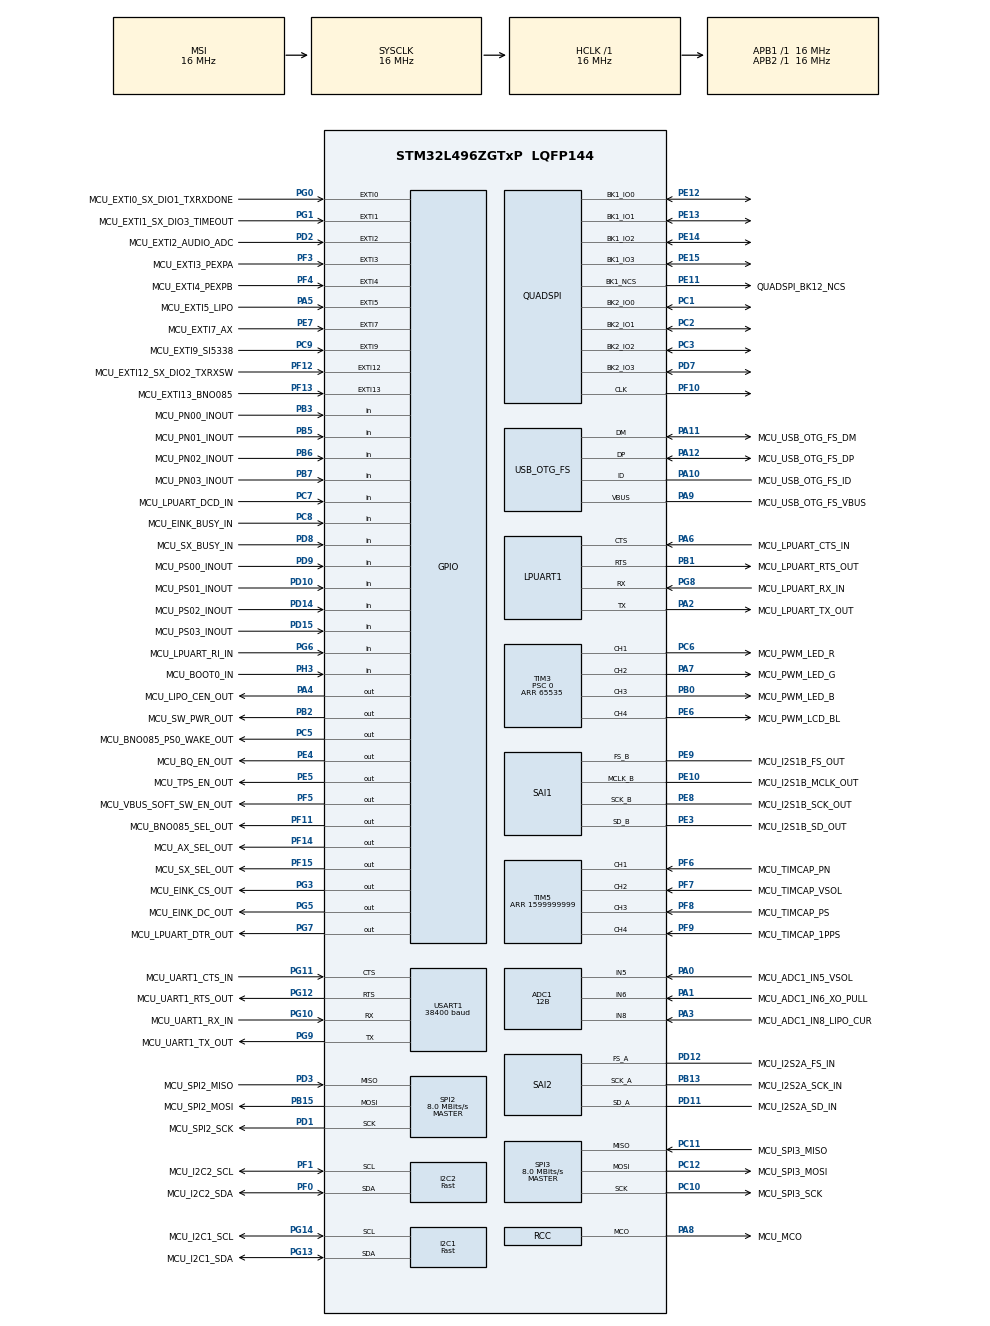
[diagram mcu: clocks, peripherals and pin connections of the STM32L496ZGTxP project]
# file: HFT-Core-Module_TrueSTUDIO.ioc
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ADC1.Channel-355\#ChannelRegularConversion=ADC_CHANNEL_VREFINT
ADC1.Channel-356\#ChannelRegularConversion=ADC_CHANNEL_8
ADC1.Channel-357\#ChannelRegularConversion=ADC_CHANNEL_VBAT
ADC1.Channel-358\#ChannelRegularConversion=ADC_CHANNEL_TEMPSENSOR
ADC1.ClockPrescaler=ADC_CLOCK_ASYNC_DIV1
ADC1.ContinuousConvMode=DISABLE
ADC1.DMAContinuousRequests=ENABLE
ADC1.DataAlign=ADC_DATAALIGN_RIGHT
ADC1.DiscontinuousConvMode=DISABLE
ADC1.EOCSelection=ADC_EOC_SINGLE_CONV
ADC1.EnableAnalogWatchDog1=false
ADC1.EnableAnalogWatchDog2=false
ADC1.EnableAnalogWatchDog3=false
ADC1.EnableInjectedConversion=DISABLE
ADC1.EnableRegularConversion=ENABLE
ADC1.ExternalTrigConv=ADC_SOFTWARE_START
ADC1.ExternalTrigConvEdge=ADC_EXTERNALTRIGCONVEDGE_NONE
ADC1.LowPowerAutoWait=DISABLE
ADC1.NbrOfConversion=4
ADC1.NbrOfConversionFlag=1
ADC1.OffsetNumber-355\#ChannelRegularConversion=ADC_OFFSET_NONE
ADC1.OffsetNumber-356\#ChannelRegularConversion=ADC_OFFSET_NONE
ADC1.OffsetNumber-357\#ChannelRegularConversion=ADC_OFFSET_NONE
ADC1.OffsetNumber-358\#ChannelRegularConversion=ADC_OFFSET_NONE
ADC1.Overrun=ADC_OVR_DATA_PRESERVED
ADC1.OversamplingMode=ENABLE
ADC1.OversamplingStopReset=ADC_REGOVERSAMPLING_CONTINUED_MODE
ADC1.Rank-355\#ChannelRegularConversion=1
ADC1.Rank-356\#ChannelRegularConversion=2
ADC1.Rank-357\#ChannelRegularConversion=3
ADC1.Rank-358\#ChannelRegularConversion=4
ADC1.Ratio=ADC_OVERSAMPLING_RATIO_16
ADC1.Resolution=ADC_RESOLUTION_12B
ADC1.RightBitShift=ADC_RIGHTBITSHIFT_NONE
ADC1.SamplingTime-355\#ChannelRegularConversion=ADC_SAMPLETIME_12CYCLES_5
ADC1.SamplingTime-356\#ChannelRegularConversion=ADC_SAMPLETIME_12CYCLES_5
ADC1.SamplingTime-357\#ChannelRegularConversion=ADC_SAMPLETIME_247CYCLES_5
ADC1.SamplingTime-358\#ChannelRegularConversion=ADC_SAMPLETIME_12CYCLES_5
ADC1.ScanConvMode=ADC_SCAN_ENABLE
ADC1.TriggeredMode=ADC_TRIGGEREDMODE_SINGLE_TRIGGER
ADC1.master=1
DFSDM1.Filter_regChannel_FIL0=DFSDM_CHANNEL_0
DFSDM1.Filter_regChannel_FIL1=DFSDM_CHANNEL_1
DFSDM1.Filter_regContinuousMode_FIL0=DFSDM_CONTINUOUS_CONV_OFF
DFSDM1.Filter_regContinuousMode_FIL1=DFSDM_CONTINUOUS_CONV_OFF
Dma.ADC1.2.Direction=DMA_PERIPH_TO_MEMORY
Dma.ADC1.2.Instance=DMA1_Channel1
Dma.ADC1.2.MemDataAlignment=DMA_MDATAALIGN_HALFWORD
Dma.ADC1.2.MemInc=DMA_MINC_ENABLE
Dma.ADC1.2.Mode=DMA_NORMAL
Dma.ADC1.2.PeriphDataAlignment=DMA_PDATAALIGN_HALFWORD
Dma.ADC1.2.PeriphInc=DMA_PINC_DISABLE
Dma.ADC1.2.Priority=DMA_PRIORITY_LOW
Dma.Request0=SAI2_A
Dma.Request1=SAI1_B
Dma.Request2=ADC1
Dma.Request3=SPI3_RX
Dma.Request4=SPI3_TX
Dma.SAI1_B.1.Direction=DMA_MEMORY_TO_PERIPH
Dma.SAI1_B.1.Instance=DMA2_Channel7
Dma.SAI1_B.1.MemDataAlignment=DMA_MDATAALIGN_WORD
Dma.SAI1_B.1.MemInc=DMA_MINC_ENABLE
Dma.SAI1_B.1.Mode=DMA_NORMAL
Dma.SAI1_B.1.PeriphDataAlignment=DMA_PDATAALIGN_WORD
Dma.SAI1_B.1.PeriphInc=DMA_PINC_DISABLE
Dma.SAI1_B.1.Priority=DMA_PRIORITY_LOW
Dma.SAI2_A.0.Direction=DMA_PERIPH_TO_MEMORY
Dma.SAI2_A.0.Instance=DMA1_Channel6
Dma.SAI2_A.0.MemDataAlignment=DMA_MDATAALIGN_WORD
Dma.SAI2_A.0.MemInc=DMA_MINC_ENABLE
Dma.SAI2_A.0.Mode=DMA_NORMAL
Dma.SAI2_A.0.PeriphDataAlignment=DMA_PDATAALIGN_WORD
Dma.SAI2_A.0.PeriphInc=DMA_PINC_DISABLE
Dma.SAI2_A.0.Priority=DMA_PRIORITY_LOW
Dma.SPI3_RX.3.Direction=DMA_PERIPH_TO_MEMORY
Dma.SPI3_RX.3.Instance=DMA2_Channel1
Dma.SPI3_RX.3.MemDataAlignment=DMA_MDATAALIGN_BYTE
Dma.SPI3_RX.3.MemInc=DMA_MINC_ENABLE
Dma.SPI3_RX.3.Mode=DMA_NORMAL
Dma.SPI3_RX.3.PeriphDataAlignment=DMA_PDATAALIGN_BYTE
Dma.SPI3_RX.3.PeriphInc=DMA_PINC_DISABLE
Dma.SPI3_RX.3.Priority=DMA_PRIORITY_LOW
Dma.SPI3_TX.4.Direction=DMA_MEMORY_TO_PERIPH
Dma.SPI3_TX.4.Instance=DMA2_Channel2
Dma.SPI3_TX.4.MemDataAlignment=DMA_MDATAALIGN_BYTE
Dma.SPI3_TX.4.MemInc=DMA_MINC_ENABLE
Dma.SPI3_TX.4.Mode=DMA_NORMAL
Dma.SPI3_TX.4.PeriphDataAlignment=DMA_PDATAALIGN_BYTE
Dma.SPI3_TX.4.PeriphInc=DMA_PINC_DISABLE
Dma.SPI3_TX.4.Priority=DMA_PRIORITY_LOW
FREERTOS.BinarySemaphores01=c2Ax5243_BSem,Dynamic,NULL;c2Sx1276_BSem,Dynamic,NULL;c2Si5338_BSem,Dynamic,NULL;c2Tcxo_BSem,Dynamic,NULL;c2Baro_BSem,Dynamic,NULL;c2Gyro_BSem,Dynamic,NULL;c2Hygro_BSem,Dynamic,NULL;c2Lcd_BSem,Dynamic,NULL;c2Default_BSem,Dynamic,NULL;i2c1_BSem,Dynamic,NULL;i2c2_BSem,Dynamic,NULL;i2c3_BSem,Dynamic,NULL;i2c4_BSem,Dynamic,NULL;spi1_BSem,Dynamic,NULL;spi3_BSem,Dynamic,NULL;cQin_BSem,Dynamic,NULL;cQout_BSem,Dynamic,NULL;c2AudioAdc_BSem,Dynamic,NULL;c2AudioDac_BSem,Dynamic,NULL;c2usbToHost_BSem,Dynamic,NULL;c2usbFromHost_BSem,Dynamic,NULL;usb_BSem,Dynamic,NULL
FREERTOS.INCLUDE_eTaskGetState=1
FREERTOS.INCLUDE_pcTaskGetTaskName=1
FREERTOS.INCLUDE_uxTaskGetStackHighWaterMark=1
FREERTOS.INCLUDE_vTaskCleanUpResources=1
FREERTOS.INCLUDE_vTaskDelayUntil=1
FREERTOS.INCLUDE_vTaskDelete=1
FREERTOS.INCLUDE_xEventGroupSetBitFromISR=1
FREERTOS.INCLUDE_xQueueGetMutexHolder=1
FREERTOS.INCLUDE_xSemaphoreGetMutexHolder=1
FREERTOS.INCLUDE_xTaskAbortDelay=1
FREERTOS.INCLUDE_xTaskGetCurrentTaskHandle=1
FREERTOS.INCLUDE_xTaskGetHandle=1
FREERTOS.INCLUDE_xTimerPendFunctionCall=1
FREERTOS.Queues01=usbToHostQueue,4096,uint8_t,0,Dynamic,NULL,NULL;usbFromHostQueue,32,uint8_t,0,Dynamic,NULL,NULL;controllerInQueue,8,uint32_t,0,Dynamic,NULL,NULL;controllerOutQueue,32,uint32_t,0,Dynamic,NULL,NULL;loraMacQueue,32,uint8_t,0,Dynamic,NULL,NULL
FREERTOS.Tasks01=defaultTask,-1,256,StartDefaultTask,Default,NULL,Dynamic,NULL,NULL;usbToHostTask,0,128,StartUsbToHostTask,Default,NULL,Dynamic,NULL,NULL;usbFromHostTask,0,128,StartUsbFromHostTask,Default,NULL,Dynamic,NULL,NULL;hygroTask,0,256,StartHygroTask,Default,NULL,Dynamic,NULL,NULL;baroTask,0,256,StartBaroTask,Default,NULL,Dynamic,NULL,NULL;gyroTask,0,256,StartGyroTask,Default,NULL,Dynamic,NULL,NULL;lcdTask,0,256,StartLcdTask,Default,NULL,Dynamic,NULL,NULL;tcxo20MhzTask,0,256,StartTcxo20MhzTask,Default,NULL,Dynamic,NULL,NULL;ax5243Task,1,512,StartAx5243Task,Default,NULL,Dynamic,NULL,NULL;sx1276Task,1,512,StartSx1276Task,Default,NULL,Dynamic,NULL,NULL;controllerTask,-2,256,StartControllerTask,Default,NULL,Dynamic,NULL,NULL;si5338Task,0,256,StartSi5338Task,Default,NULL,Dynamic,NULL,NULL;audioAdcTask,0,256,StartAudioAdcTask,Default,NULL,Dynamic,NULL,NULL;audioDacTask,0,256,StartAudioDacTask,Default,NULL,Dynamic,NULL,NULL
FREERTOS.Timers01=baroTimer,rtosBaroTimerCallback,osTimerPeriodic,Default,NULL,Dynamic,NULL;hygroTimer,rtosHygroTimerCallback,osTimerPeriodic,Default,NULL,Dynamic,NULL;defaultTimer,rtosDefaultTimerCallback,osTimerPeriodic,Default,NULL,Dynamic,NULL;gyroTimer,rtosGyroTimerCallback,osTimerPeriodic,Default,NULL,Dynamic,NULL;controllerTimer,rtosControllerTimerCallback,osTimerPeriodic,Default,NULL,Dynamic,NULL;tcxoTimer,rtosTcxoTimerCallback,osTimerPeriodic,Default,NULL,Dynamic,NULL;audioAdcTimer,rtosAudioAdcTimerCallback,osTimerPeriodic,Default,NULL,Dynamic,NULL;audioDacTimer,rtosAudioDacTimerCallback,osTimerPeriodic,Default,NULL,Dynamic,NULL
FREERTOS.configCHECK_FOR_STACK_OVERFLOW=1
FREERTOS.configENABLE_BACKWARD_COMPATIBILITY=0
FREERTOS.configGENERATE_RUN_TIME_STATS=1
FREERTOS.configMAX_TASK_NAME_LEN=32
FREERTOS.configQUEUE_REGISTRY_SIZE=64
FREERTOS.configTIMER_QUEUE_LENGTH=16
FREERTOS.configTOTAL_HEAP_SIZE=0x8000
FREERTOS.configUSE_APPLICATION_TASK_TAG=1
FREERTOS.configUSE_COUNTING_SEMAPHORES=1
FREERTOS.configUSE_IDLE_HOOK=1
FREERTOS.configUSE_MALLOC_FAILED_HOOK=1
FREERTOS.configUSE_RECURSIVE_MUTEXES=1
FREERTOS.configUSE_STATS_FORMATTING_FUNCTIONS=1
FREERTOS.configUSE_TICKLESS_IDLE=0
FREERTOS.configUSE_TIMERS=1
FREERTOS.configUSE_TRACE_FACILITY=1
I2C1.I2C_Coeff_DF=3
I2C1.I2C_Fall_Time=25
I2C1.I2C_Rise_Time=120
I2C1.I2C_Speed_Mode=I2C_Fast
I2C1.Timing=0x00300711
I2C2.I2C_Coeff_DF=3
I2C2.I2C_Fall_Time=25
I2C2.I2C_Rise_Time=120
I2C2.I2C_Speed_Mode=I2C_Fast
I2C2.Timing=0x00300711
Mcu.Family=STM32L4
Mcu.Name=STM32L496ZGTxP
Mcu.Package=LQFP144
NVIC.ADC1_2_IRQn=true\:5\:0\:false\:false\:true\:true\:true
NVIC.DMA1_Channel1_IRQn=true\:5\:0\:false\:false\:true\:true\:false
NVIC.DMA1_Channel6_IRQn=true\:5\:0\:false\:false\:true\:true\:false
NVIC.DMA2_Channel1_IRQn=true\:5\:0\:false\:false\:true\:true\:false
NVIC.DMA2_Channel2_IRQn=true\:5\:0\:false\:false\:true\:true\:false
NVIC.DMA2_Channel7_IRQn=true\:5\:0\:false\:false\:true\:true\:false
NVIC.HASH_RNG_IRQn=true\:5\:0\:false\:false\:true\:true\:true
NVIC.I2C1_ER_IRQn=true\:5\:0\:false\:false\:true\:true\:true
NVIC.I2C1_EV_IRQn=true\:5\:0\:false\:false\:true\:true\:true
NVIC.I2C2_ER_IRQn=true\:5\:0\:false\:false\:true\:true\:true
NVIC.I2C2_EV_IRQn=true\:5\:0\:false\:false\:true\:true\:true
NVIC.PriorityGroup=NVIC_PRIORITYGROUP_4
NVIC.RTC_Alarm_IRQn=true\:5\:0\:false\:false\:true\:true\:true
NVIC.SAI1_IRQn=true\:5\:0\:false\:false\:true\:true\:true
NVIC.SAI2_IRQn=true\:5\:0\:false\:false\:true\:true\:true
NVIC.TIM2_IRQn=true\:0\:0\:false\:false\:true\:false\:false
NVIC.TimeBase=TIM2_IRQn
NVIC.TimeBaseIP=TIM2
PA0.GPIO_Label=MCU_ADC1_IN5_VSOL
PA0.Signal=ADCx_IN5
PA1.GPIO_Label=MCU_ADC1_IN6_XO_PULL
PA1.Signal=ADCx_IN6
PA10.GPIO_Label=MCU_USB_OTG_FS_ID
PA10.Mode=OTG/Dual_Role_Device
PA10.Signal=USB_OTG_FS_ID
PA11.GPIO_Label=MCU_USB_OTG_FS_DM
PA11.GPIO_PuPd=GPIO_NOPULL
PA11.GPIO_Speed=GPIO_SPEED_FREQ_HIGH
PA11.Mode=OTG/Dual_Role_Device
PA11.Signal=USB_OTG_FS_DM
PA12.GPIO_Label=MCU_USB_OTG_FS_DP
PA12.GPIO_PuPd=GPIO_NOPULL
PA12.GPIO_Speed=GPIO_SPEED_FREQ_HIGH
PA12.Mode=OTG/Dual_Role_Device
PA12.Signal=USB_OTG_FS_DP
PA13\ (JTMS/SWDIO).GPIO_Label=MCU_SWDIO
PA13\ (JTMS/SWDIO).Mode=Serial_Wire
PA13\ (JTMS/SWDIO).Signal=SYS_JTMS-SWDIO
PA14\ (JTCK/SWCLK).GPIO_Label=MCU_SWCLK
PA14\ (JTCK/SWCLK).Mode=Serial_Wire
PA14\ (JTCK/SWCLK).Signal=SYS_JTCK-SWCLK
PA2.GPIO_Label=MCU_LPUART_TX_OUT
PA2.Mode=Asynchronous
PA2.Signal=LPUART1_TX
PA3.GPIO_Label=MCU_ADC1_IN8_LIPO_CUR
PA3.Signal=ADCx_IN8
PA4.GPIO_Label=MCU_LIPO_CEN_OUT
PA4.Signal=GPIO_Output
PA5.GPIO_Label=MCU_EXTI5_LIPO
PA5.Signal=GPXTI5
PA6.GPIO_Label=MCU_LPUART_CTS_IN
PA6.Mode=CTS_RTS
PA6.Signal=LPUART1_CTS
PA7.GPIO_Label=MCU_PWM_LED_G
PA7.GPIO_PuPd=GPIO_NOPULL
PA7.Signal=S_TIM3_CH2
PA8.GPIO_Label=MCU_MCO
PA8.GPIO_PuPd=GPIO_NOPULL
PA8.GPIO_Speed=GPIO_SPEED_FREQ_LOW
PA8.Mode=Clock-out
PA8.Signal=RCC_MCO
PA9.GPIO_Label=MCU_USB_OTG_FS_VBUS
PA9.GPIO_PuPd=GPIO_PULLDOWN
PA9.Mode=Activate_VBUS
PA9.Signal=USB_OTG_FS_VBUS
PB0.GPIO_Label=MCU_PWM_LED_B
PB0.GPIO_PuPd=GPIO_NOPULL
PB0.Signal=S_TIM3_CH3
PB1.GPIO_Label=MCU_LPUART_RTS_OUT
PB1.Mode=CTS_RTS
PB1.Signal=LPUART1_RTS
PB13.GPIO_Label=MCU_I2S2A_SCK_IN
PB13.GPIO_PuPd=GPIO_PULLDOWN
PB13.GPIO_Speed=GPIO_SPEED_FREQ_MEDIUM
PB13.Mode=SAI_A_AsyncSlave
PB13.Signal=SAI2_SCK_A
PB15.GPIO_Label=MCU_SPI2_MOSI
PB15.Mode=Full_Duplex_Master
PB15.Signal=SPI2_MOSI
PB2.GPIO_Label=MCU_SW_PWR_OUT
PB2.Signal=GPIO_Output
PB3\ (JTDO/TRACESWO).GPIO_Label=MCU_PN00_INOUT
PB3\ (JTDO/TRACESWO).GPIO_PuPd=GPIO_PULLDOWN
PB3\ (JTDO/TRACESWO).Signal=GPIO_Input
PB5.GPIO_Label=MCU_PN01_INOUT
PB5.GPIO_PuPd=GPIO_PULLDOWN
PB5.Signal=GPIO_Input
PB6.GPIO_Label=MCU_PN02_INOUT
PB6.GPIO_PuPd=GPIO_PULLDOWN
PB6.Signal=GPIO_Input
PB7.GPIO_Label=MCU_PN03_INOUT
PB7.GPIO_PuPd=GPIO_PULLDOWN
PB7.Signal=GPIO_Input
PC1.Mode=Dual Bank
PC1.Signal=QUADSPI_BK2_IO0
PC10.GPIO_Label=MCU_SPI3_SCK
PC10.GPIO_PuPd=GPIO_NOPULL
PC10.GPIO_Speed=GPIO_SPEED_FREQ_VERY_HIGH
PC10.Mode=Full_Duplex_Master
PC10.Signal=SPI3_SCK
PC11.GPIO_Label=MCU_SPI3_MISO
PC11.GPIO_PuPd=GPIO_PULLDOWN
PC11.GPIO_Speed=GPIO_SPEED_FREQ_VERY_HIGH
PC11.Mode=Full_Duplex_Master
PC11.Signal=SPI3_MISO
PC12.GPIO_Label=MCU_SPI3_MOSI
PC12.GPIO_PuPd=GPIO_NOPULL
PC12.GPIO_Speed=GPIO_SPEED_FREQ_VERY_HIGH
PC12.Mode=Full_Duplex_Master
PC12.Signal=SPI3_MOSI
PC13.GPIO_Label=MCU_WAKEUP_IN
PC13.Mode=SYS_WakeUp1
PC13.Signal=SYS_WKUP2
PC14-OSC32_IN\ (PC14).GPIO_Label=MCU_OSC32_IN
PC14-OSC32_IN\ (PC14).Mode=LSE-External-Oscillator
PC14-OSC32_IN\ (PC14).Signal=RCC_OSC32_IN
PC15-OSC32_OUT\ (PC15).GPIO_Label=MCU_OSC32_OUT
PC15-OSC32_OUT\ (PC15).Mode=LSE-External-Oscillator
PC15-OSC32_OUT\ (PC15).Signal=RCC_OSC32_OUT
PC2.Mode=Dual Bank
PC2.Signal=QUADSPI_BK2_IO1
PC3.Mode=Dual Bank
PC3.Signal=QUADSPI_BK2_IO2
PC5.GPIO_Label=MCU_BNO085_PS0_WAKE_OUT
PC5.Signal=GPIO_Output
PC6.GPIO_Label=MCU_PWM_LED_R
PC6.GPIO_PuPd=GPIO_NOPULL
PC6.Signal=S_TIM3_CH1
PC7.GPIO_Label=MCU_LPUART_DCD_IN
PC7.Signal=GPIO_Input
PC8.GPIO_Label=MCU_EINK_BUSY_IN
PC8.Signal=GPIO_Input
PC9.GPIO_Label=MCU_EXTI9_SI5338
PC9.Signal=GPXTI9
PD1.GPIO_Label=MCU_SPI2_SCK
PD1.Mode=Full_Duplex_Master
PD1.Signal=SPI2_SCK
PD10.GPIO_Label=MCU_PS01_INOUT
PD10.GPIO_PuPd=GPIO_PULLDOWN
PD10.Signal=GPIO_Input
PD11.GPIO_Label=MCU_I2S2A_SD_IN
PD11.GPIO_PuPd=GPIO_PULLDOWN
PD11.GPIO_Speed=GPIO_SPEED_FREQ_MEDIUM
PD11.Mode=SAI_A_AsyncSlave
PD11.Signal=SAI2_SD_A
PD12.GPIO_Label=MCU_I2S2A_FS_IN
PD12.GPIO_PuPd=GPIO_PULLDOWN
PD12.GPIO_Speed=GPIO_SPEED_FREQ_MEDIUM
PD12.Mode=SAI_A_AsyncSlave
PD12.Signal=SAI2_FS_A
PD14.GPIO_Label=MCU_PS02_INOUT
PD14.GPIO_PuPd=GPIO_PULLDOWN
PD14.Signal=GPIO_Input
PD15.GPIO_Label=MCU_PS03_INOUT
PD15.GPIO_PuPd=GPIO_PULLDOWN
PD15.Signal=GPIO_Input
PD2.GPIO_Label=MCU_EXTI2_AUDIO_ADC
PD2.Signal=GPXTI2
PD3.GPIO_Label=MCU_SPI2_MISO
PD3.GPIO_PuPd=GPIO_PULLDOWN
PD3.Mode=Full_Duplex_Master
PD3.Signal=SPI2_MISO
PD7.Mode=Dual Bank
PD7.Signal=QUADSPI_BK2_IO3
PD8.GPIO_Label=MCU_SX_BUSY_IN
PD8.Signal=GPIO_Input
PD9.GPIO_Label=MCU_PS00_INOUT
PD9.GPIO_PuPd=GPIO_PULLDOWN
PD9.Signal=GPIO_Input
PE10.GPIO_Label=MCU_I2S1B_MCLK_OUT
PE10.GPIO_PuPd=GPIO_NOPULL
PE10.GPIO_Speed=GPIO_SPEED_FREQ_MEDIUM
PE10.Mode=SAI_B_MasterWithClock
PE10.Signal=SAI1_MCLK_B
PE11.GPIO_Label=QUADSPI_BK12_NCS
PE11.Mode=Enable Chip Select 1 for both banks
PE11.Signal=QUADSPI_BK1_NCS
PE12.Mode=Dual Bank
PE12.Signal=QUADSPI_BK1_IO0
PE13.Mode=Dual Bank
PE13.Signal=QUADSPI_BK1_IO1
PE14.Mode=Dual Bank
PE14.Signal=QUADSPI_BK1_IO2
PE15.Mode=Dual Bank
PE15.Signal=QUADSPI_BK1_IO3
PE3.GPIO_Label=MCU_I2S1B_SD_OUT
PE3.GPIO_PuPd=GPIO_NOPULL
PE3.GPIO_Speed=GPIO_SPEED_FREQ_MEDIUM
PE3.Mode=SAI_B_MasterWithClock
PE3.Signal=SAI1_SD_B
PE4.GPIO_Label=MCU_BQ_EN_OUT
PE4.Signal=GPIO_Output
PE5.GPIO_Label=MCU_TPS_EN_OUT
PE5.PinState=GPIO_PIN_SET
PE5.Signal=GPIO_Output
PE6.GPIO_Label=MCU_PWM_LCD_BL
PE6.Signal=S_TIM3_CH4
PE7.GPIO_Label=MCU_EXTI7_AX
PE7.Signal=GPXTI7
PE8.GPIO_Label=MCU_I2S1B_SCK_OUT
PE8.GPIO_PuPd=GPIO_NOPULL
PE8.GPIO_Speed=GPIO_SPEED_FREQ_MEDIUM
PE8.Mode=SAI_B_MasterWithClock
PE8.Signal=SAI1_SCK_B
PE9.GPIO_Label=MCU_I2S1B_FS_OUT
PE9.GPIO_PuPd=GPIO_NOPULL
PE9.GPIO_Speed=GPIO_SPEED_FREQ_MEDIUM
PE9.Mode=SAI_B_MasterWithClock
PE9.Signal=SAI1_FS_B
PF0.GPIO_Label=MCU_I2C2_SDA
PF0.GPIO_PuPdOD=GPIO_NOPULL
PF0.GPIO_Speed=GPIO_SPEED_FREQ_HIGH
PF0.Mode=I2C
PF0.Signal=I2C2_SDA
PF1.GPIO_Label=MCU_I2C2_SCL
PF1.GPIO_PuPdOD=GPIO_NOPULL
PF1.GPIO_Speed=GPIO_SPEED_FREQ_HIGH
PF1.Mode=I2C
PF1.Signal=I2C2_SCL
PF10.Mode=Dual Bank
PF10.Signal=QUADSPI_CLK
PF11.GPIO_Label=MCU_BNO085_SEL_OUT
PF11.Signal=GPIO_Output
PF12.GPIO_Label=MCU_EXTI12_SX_DIO2_TXRXSW
PF12.Signal=GPXTI12
PF13.GPIO_Label=MCU_EXTI13_BNO085
PF13.Signal=GPXTI13
PF14.GPIO_Label=MCU_AX_SEL_OUT
PF14.Signal=GPIO_Output
PF15.GPIO_Label=MCU_SX_SEL_OUT
PF15.Signal=GPIO_Output
PF3.GPIO_Label=MCU_EXTI3_PEXPA
PF3.Signal=GPXTI3
PF4.GPIO_Label=MCU_EXTI4_PEXPB
PF4.Signal=GPXTI4
PF5.GPIO_Label=MCU_VBUS_SOFT_SW_EN_OUT
PF5.Signal=GPIO_Output
PF6.GPIO_Label=MCU_TIMCAP_PN
PF6.GPIO_PuPd=GPIO_PULLDOWN
PF6.Signal=S_TIM5_CH1
PF7.GPIO_Label=MCU_TIMCAP_VSOL
PF7.GPIO_PuPd=GPIO_PULLDOWN
PF7.Signal=S_TIM5_CH2
PF8.GPIO_Label=MCU_TIMCAP_PS
PF8.GPIO_PuPd=GPIO_PULLDOWN
PF8.Signal=S_TIM5_CH3
PF9.GPIO_Label=MCU_TIMCAP_1PPS
PF9.GPIO_PuPd=GPIO_PULLDOWN
PF9.Signal=S_TIM5_CH4
PG0.GPIO_Label=MCU_EXTI0_SX_DIO1_TXRXDONE
PG0.Signal=GPXTI0
PG1.GPIO_Label=MCU_EXTI1_SX_DIO3_TIMEOUT
PG1.Signal=GPXTI1
PG10.GPIO_Label=MCU_UART1_RX_IN
PG10.GPIO_PuPd=GPIO_PULLUP
PG10.GPIO_Speed=GPIO_SPEED_FREQ_LOW
PG10.Mode=Asynchronous
PG10.Signal=USART1_RX
PG11.GPIO_Label=MCU_UART1_CTS_IN
PG11.GPIO_PuPd=GPIO_PULLDOWN
PG11.GPIO_Speed=GPIO_SPEED_FREQ_LOW
PG11.Mode=CTS_RTS
PG11.Signal=USART1_CTS
PG12.GPIO_Label=MCU_UART1_RTS_OUT
PG12.GPIO_PuPd=GPIO_NOPULL
PG12.GPIO_Speed=GPIO_SPEED_FREQ_LOW
PG12.Mode=CTS_RTS
PG12.Signal=USART1_RTS
PG13.GPIO_Label=MCU_I2C1_SDA
PG13.GPIO_PuPdOD=GPIO_NOPULL
PG13.GPIO_Speed=GPIO_SPEED_FREQ_HIGH
PG13.Mode=I2C
PG13.Signal=I2C1_SDA
PG14.GPIO_Label=MCU_I2C1_SCL
PG14.GPIO_PuPdOD=GPIO_NOPULL
PG14.GPIO_Speed=GPIO_SPEED_FREQ_HIGH
PG14.Mode=I2C
PG14.Signal=I2C1_SCL
PG3.GPIO_Label=MCU_EINK_CS_OUT
PG3.Signal=GPIO_Output
PG4.GPIO_Label=MCU_EVENTOUT
PG4.GPIO_PuPd=GPIO_NOPULL
PG4.Signal=EVENTOUT
PG5.GPIO_Label=MCU_EINK_DC_OUT
PG5.Signal=GPIO_Output
PG6.GPIO_Label=MCU_LPUART_RI_IN
PG6.Signal=GPIO_Input
PG7.GPIO_Label=MCU_LPUART_DTR_OUT
PG7.Signal=GPIO_Output
PG8.GPIO_Label=MCU_LPUART_RX_IN
PG8.Mode=Asynchronous
PG8.Signal=LPUART1_RX
PG9.GPIO_Label=MCU_UART1_TX_OUT
PG9.GPIO_PuPd=GPIO_NOPULL
PG9.GPIO_Speed=GPIO_SPEED_FREQ_LOW
PG9.Mode=Asynchronous
PG9.Signal=USART1_TX
PH0-OSC_IN\ (PH0).GPIO_Label=MCU_HSE
PH0-OSC_IN\ (PH0).Mode=HSE-External-Clock-Source
PH0-OSC_IN\ (PH0).Signal=RCC_OSC_IN
PH3-BOOT0.GPIO_Label=MCU_BOOT0_IN
PH3-BOOT0.Signal=GPIO_Input
ProjectManager.HeapSize=0x200
ProjectManager.StackSize=0x400
ProjectManager.TargetToolchain=TrueSTUDIO
QUADSPI.ClockPrescaler=2
RCC.ADCCLockSelection=RCC_ADCCLKSOURCE_SYSCLK
RCC.ADCFreq_Value=16000000
RCC.AHBFreq_Value=16000000
RCC.APB1Freq_Value=16000000
RCC.APB1TimFreq_Value=16000000
RCC.APB2Freq_Value=16000000
RCC.APB2TimFreq_Value=16000000
RCC.CK48CLockSelection=RCC_USBCLKSOURCE_HSI48
RCC.CortexFreq_Value=16000000
RCC.HCLKFreq_Value=16000000
RCC.HSE_VALUE=20000000
RCC.HSI48_VALUE=48000000
RCC.HSI_VALUE=16000000
RCC.I2C1CLockSelection=RCC_I2C1CLKSOURCE_SYSCLK
RCC.I2C2CLockSelection=RCC_I2C2CLKSOURCE_SYSCLK
RCC.I2C3CLockSelection=RCC_I2C3CLKSOURCE_SYSCLK
RCC.I2C4CLockSelection=RCC_I2C4CLKSOURCE_SYSCLK
RCC.MSIClockRange=RCC_MSIRANGE_8
RCC.MSI_VALUE=16000000
RCC.PLLM=4
RCC.PLLN=16
RCC.PLLP=RCC_PLLP_DIV24
RCC.PLLQ=RCC_PLLQ_DIV8
RCC.PLLSAI1N=16
RCC.PLLSAI1P=RCC_PLLP_DIV24
RCC.PLLSAI1Q=RCC_PLLQ_DIV8
RCC.PLLSAI1R=RCC_PLLR_DIV8
RCC.PLLSAI2P=RCC_PLLP_DIV12
RCC.PLLSAI2R=RCC_PLLR_DIV8
RCC.PREFETCH_ENABLE=1
RCC.PWR_Regulator_Voltage_Scale=PWR_REGULATOR_VOLTAGE_SCALE2
RCC.RCC_MCO1Source=RCC_MCO1SOURCE_MSI
RCC.RCC_MCODiv=RCC_MCODIV_2
RCC.RTCClockSelection=RCC_RTCCLKSOURCE_LSE
RCC.SAI1CLockSelection=RCC_SAI1CLKSOURCE_PLL
RCC.SAI2CLockSelection=RCC_SAI2CLKSOURCE_PLL
RCC.SYSCLKFreq_VALUE=16000000
RCC.USBFreq_Value=48000000
RCC.VCOOutputFreq_Value=64000000
RTC.Alarm-Alarm\ A=RTC_ALARM_A
RTC.AlarmMaskDateWeekDay-Alarm\ A=RTC_ALARMMASK_DATEWEEKDAY
RTC.AlarmMaskHours-Alarm\ A=RTC_ALARMMASK_HOURS
RTC.AlarmMaskMinutes-Alarm\ A=RTC_ALARMMASK_MINUTES
RTC.AlarmMaskSeconds-Alarm\ A=RTC_ALARMMASK_SECONDS
RTC.Alarm_B-Alarm\ B=RTC_ALARM_B
RTC.AsynchPrediv=31
RTC.Format=RTC_FORMAT_BIN
RTC.SynchPrediv=1023
RTC.Year=18
SAI1.ErrorAudioFreq-SAI_B_MasterWithClock=-51.17 %
SAI1.FIFOThreshold-SAI_B_MasterWithClock=SAI_FIFOTHRESHOLD_HF
SAI1.InitProtocol-SAI_B_MasterWithClock=Enable
SAI1.Instance-SAI_B_MasterWithClock=SAI$Index_Block_B
SAI1.MClockEnable-SAI_B_MasterWithClock=SAI_MASTERCLOCK_ENABLE
SAI1.NoDivider-SAI_B_MasterWithClock=SAI_MASTERDIVIDER_ENABLE
SAI1.RealAudioFreq-SAI_B_MasterWithClock=93.75 KHz
SAI1.Synchro-SAI_B_MasterWithClock=SAI_ASYNCHRONOUS
SAI1.VirtualMode-SAI_B_MasterWithClock=VM_MASTER
SAI1.VirtualProtocol-SAI_B_BASIC=VM_BASIC_PROTOCOL
SAI2.FIFOThreshold-SAI_A_AsyncSlave=SAI_FIFOTHRESHOLD_1QF
SAI2.InitProtocol-SAI_A_AsyncSlave=Enable
SAI2.Instance-SAI_A_AsyncSlave=SAI$Index_Block_A
SAI2.Synchro-SAI_A_AsyncSlave=SAI_ASYNCHRONOUS
SAI2.VirtualMode-SAI_A_AsyncSlave=VM_SLAVE
SAI2.VirtualProtocol-SAI_A_BASIC=VM_BASIC_PROTOCOL
SH.ADCx_IN5.0=ADC1_IN5,IN5-Single-Ended
SH.ADCx_IN6.0=ADC1_IN6,IN6-Single-Ended
SH.ADCx_IN8.0=ADC1_IN8,IN8-Single-Ended
SH.S_TIM3_CH1.0=TIM3_CH1,PWM Generation1 CH1
SH.S_TIM3_CH2.0=TIM3_CH2,PWM Generation2 CH2
SH.S_TIM3_CH3.0=TIM3_CH3,PWM Generation3 CH3
SH.S_TIM3_CH4.0=TIM3_CH4,PWM Generation4 CH4
SH.S_TIM5_CH1.0=TIM5_CH1,Input_Capture1_from_TI1
SH.S_TIM5_CH2.0=TIM5_CH2,Input_Capture2_from_TI2
SH.S_TIM5_CH3.0=TIM5_CH3,Input_Capture3_from_TI3
SH.S_TIM5_CH4.0=TIM5_CH4,Input_Capture4_from_TI4
SPI2.CalculateBaudRate=8.0 MBits/s
SPI2.DataSize=SPI_DATASIZE_8BIT
SPI2.Direction=SPI_DIRECTION_2LINES
SPI2.Mode=SPI_MODE_MASTER
SPI2.NSSPMode=SPI_NSS_PULSE_DISABLE
SPI2.VirtualType=VM_MASTER
SPI3.BaudRatePrescaler=SPI_BAUDRATEPRESCALER_2
SPI3.CalculateBaudRate=8.0 MBits/s
SPI3.DataSize=SPI_DATASIZE_8BIT
SPI3.Direction=SPI_DIRECTION_2LINES
SPI3.Mode=SPI_MODE_MASTER
SPI3.NSSPMode=SPI_NSS_PULSE_DISABLE
SPI3.VirtualType=VM_MASTER
SYS.PVDLevel=PWR_PVDLEVEL_5
SYS.TrimmingMode=USER_TRIMMING
SYS.TrimmingValue=5
TIM16.AutoReloadPreload=TIM_AUTORELOAD_PRELOAD_ENABLE
TIM16.Channel=TIM_CHANNEL_1
TIM16.Period=65535
TIM16.Prescaler=0
TIM16.TIM16_TI1_REMAP=TIM_TIM16_TI1_LSE
TIM17.AutoReloadPreload=TIM_AUTORELOAD_PRELOAD_ENABLE
TIM17.Channel=TIM_CHANNEL_1
TIM17.Period=65535
TIM3.AutoReloadPreload=TIM_AUTORELOAD_PRELOAD_ENABLE
TIM3.Channel-PWM\ Generation1\ CH1=TIM_CHANNEL_1
TIM3.Channel-PWM\ Generation2\ CH2=TIM_CHANNEL_2
TIM3.Channel-PWM\ Generation3\ CH3=TIM_CHANNEL_3
TIM3.Channel-PWM\ Generation4\ CH4=TIM_CHANNEL_4
TIM3.Period=65535
TIM3.Prescaler=0
TIM5.AutoReloadPreload=TIM_AUTORELOAD_PRELOAD_ENABLE
TIM5.Channel-Input_Capture1_from_TI1=TIM_CHANNEL_1
TIM5.Channel-Input_Capture2_from_TI2=TIM_CHANNEL_2
TIM5.Channel-Input_Capture3_from_TI3=TIM_CHANNEL_3
TIM5.Channel-Input_Capture4_from_TI4=TIM_CHANNEL_4
TIM5.Period=1599999999
USART1.BaudRate=38400
USART1.VirtualMode-Asynchronous=VM_ASYNC
USART1.WordLength=WORDLENGTH_8B
VP_ADC1_TempSens_Input.Mode=IN-TempSens
VP_ADC1_Vbat_Input.Mode=IN-Vbat
VP_ADC1_Vref_Input.Mode=IN-Vrefint
VP_CRC_VS_CRC.Mode=CRC_Activate
VP_DFSDM1_VS_IN0.Mode=Parallel_Input_ch0
VP_DFSDM1_VS_IN1.Mode=Parallel_Input_ch1
VP_FREERTOS_VS_ENABLE.Mode=Enabled
VP_RCC_USB.Mode=CRS SYNC Source USB
VP_RNG_VS_RNG.Mode=RNG_Activate
VP_RTC_VS_RTC_Activate.Mode=RTC_Enabled
VP_RTC_VS_RTC_Alarm_A_Intern.Mode=Alarm A
VP_RTC_VS_RTC_Alarm_B_Intern.Mode=Alarm B
VP_RTC_VS_RTC_Calendar.Mode=RTC_Calendar
VP_RTC_VS_RTC_WakeUp_intern.Mode=WakeUp
VP_SAI1_VP_$IpInstance_SAIB_SAI_BASIC.Mode=SAI_B_BASIC
VP_SAI2_VP_$IpInstance_SAIA_SAI_BASIC.Mode=SAI_A_BASIC
VP_SYS_VS_tim2.Mode=TIM2
VP_SYS_V_PVD_IN.Mode=Mode_PVD_Int
VP_TIM16_VS_ClockSourceINT.Mode=Enable_Timer
VP_TIM16_VS_NoInput1.Mode=Input_Capture1_from_TI1_REMAP_TIM16
VP_TIM17_VS_ClockSourceINT.Mode=Enable_Timer
VP_TIM17_VS_NoInput1.Mode=Input_Capture1_from_TI1_REMAP_TIM17
VP_TIM3_VS_ClockSourceINT.Mode=Internal
VP_TIM5_VS_ClockSourceINT.Mode=Internal
VREF+.GPIO_Label=MCU_VREF+_OUT
VREF+.Mode=InternalMode
VREF+.Signal=VREFBUF_OUT
board=HFT-Core-Module_TrueSTUDIO

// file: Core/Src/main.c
/* USER CODE BEGIN Header */
/**
  ******************************************************************************
  * @file           : main.c
  * @brief          : Main program body
  ******************************************************************************
  * This notice applies to any and all portions of this file
  * that are not between comment pairs USER CODE BEGIN and
  * USER CODE END. Other portions of this file, whether
  * inserted by the user or by software development tools
  * are owned by their respective copyright owners.
  *
  * Copyright (c) 2019 STMicroelectronics International N.V.
  * All rights reserved.
  *
  * Redistribution and use in source and binary forms, with or without
  * modification, are permitted, provided that the following conditions are met:
  *
  * 1. Redistribution of source code must retain the above copyright notice,
  *    this list of conditions and the following disclaimer.
  * 2. Redistributions in binary form must reproduce the above copyright notice,
  *    this list of conditions and the following disclaimer in the documentation
  *    and/or other materials provided with the distribution.
  * 3. Neither the name of STMicroelectronics nor the names of other
  *    contributors to this software may be used to endorse or promote products
  *    derived from this software without specific written permission.
  * 4. This software, including modifications and/or derivative works of this
  *    software, must execute solely and exclusively on microcontroller or
  *    microprocessor devices manufactured by or for STMicroelectronics.
  * 5. Redistribution and use of this software other than as permitted under
  *    this license is void and will automatically terminate your rights under
  *    this license.
  *
  * THIS SOFTWARE IS PROVIDED BY STMICROELECTRONICS AND CONTRIBUTORS "AS IS"
  * AND ANY EXPRESS, IMPLIED OR STATUTORY WARRANTIES, INCLUDING, BUT NOT
  * LIMITED TO, THE IMPLIED WARRANTIES OF MERCHANTABILITY, FITNESS FOR A
  * PARTICULAR PURPOSE AND NON-INFRINGEMENT OF THIRD PARTY INTELLECTUAL PROPERTY
  * RIGHTS ARE DISCLAIMED TO THE FULLEST EXTENT PERMITTED BY LAW. IN NO EVENT
  * SHALL STMICROELECTRONICS OR CONTRIBUTORS BE LIABLE FOR ANY DIRECT, INDIRECT,
  * INCIDENTAL, SPECIAL, EXEMPLARY, OR CONSEQUENTIAL DAMAGES (INCLUDING, BUT NOT
  * LIMITED TO, PROCUREMENT OF SUBSTITUTE GOODS OR SERVICES; LOSS OF USE, DATA,
  * OR PROFITS; OR BUSINESS INTERRUPTION) HOWEVER CAUSED AND ON ANY THEORY OF
  * LIABILITY, WHETHER IN CONTRACT, STRICT LIABILITY, OR TORT (INCLUDING
  * NEGLIGENCE OR OTHERWISE) ARISING IN ANY WAY OUT OF THE USE OF THIS SOFTWARE,
  * EVEN IF ADVISED OF THE POSSIBILITY OF SUCH DAMAGE.
  *
  ******************************************************************************
  */
/* USER CODE END Header */

#include "main.h"
#include "cmsis_os.h"
#include "adc.h"
#include "crc.h"
#include "dfsdm.h"
#include "dma.h"
#include "i2c.h"
#include "usart.h"
#include "quadspi.h"
#include "rng.h"
#include "rtc.h"
#include "sai.h"
#include "spi.h"
#include "tim.h"
#include "usb_otg.h"
#include "gpio.h"

void SystemClock_Config(void);
void MX_FREERTOS_Init(void);

int main(void)
{

  /* MCU Configuration--------------------------------------------------------*/

  /* Reset of all peripherals, Initializes the Flash interface and the Systick. */
  HAL_Init();

  /* Configure the system clock */
  SystemClock_Config();

  /* Initialize all configured peripherals */
  MX_GPIO_Init();
  MX_DMA_Init();
  MX_ADC1_Init();
  MX_CRC_Init();
  MX_DFSDM1_Init();
  MX_I2C1_Init();
  MX_I2C2_Init();
  MX_RNG_Init();
  MX_RTC_Init();
  MX_SAI1_Init();
  MX_SAI2_Init();
  MX_SPI3_Init();
  MX_TIM16_Init();
  MX_TIM17_Init();
  MX_TIM3_Init();
  MX_TIM5_Init();
  MX_USART1_UART_Init();
  MX_SPI2_Init();
  MX_QUADSPI_Init();
  MX_LPUART1_UART_Init();
  MX_USB_OTG_FS_USB_Init();

  /* Call init function for freertos objects (in freertos.c) */
  MX_FREERTOS_Init();

  /* Start scheduler */
  osKernelStart();

  /* We should never get here as control is now taken by the scheduler */

  /* Infinite loop */
  while (1)
  {

  }
}

void SystemClock_Config(void)
{
  RCC_OscInitTypeDef RCC_OscInitStruct = {0};
  RCC_ClkInitTypeDef RCC_ClkInitStruct = {0};
  RCC_PeriphCLKInitTypeDef PeriphClkInit = {0};
  RCC_CRSInitTypeDef RCC_CRSInitStruct = {0};

  /**Configure LSE Drive Capability
  */
  HAL_PWR_EnableBkUpAccess();
  __HAL_RCC_LSEDRIVE_CONFIG(RCC_LSEDRIVE_LOW);
  /**Initializes the CPU, AHB and APB busses clocks
  */
  RCC_OscInitStruct.OscillatorType = RCC_OSCILLATORTYPE_HSI48|RCC_OSCILLATORTYPE_LSE
                              |RCC_OSCILLATORTYPE_MSI;
  RCC_OscInitStruct.LSEState = RCC_LSE_ON;
  RCC_OscInitStruct.HSI48State = RCC_HSI48_ON;
  RCC_OscInitStruct.MSIState = RCC_MSI_ON;
  RCC_OscInitStruct.MSICalibrationValue = 0;
  RCC_OscInitStruct.MSIClockRange = RCC_MSIRANGE_8;
  RCC_OscInitStruct.PLL.PLLState = RCC_PLL_ON;
  RCC_OscInitStruct.PLL.PLLSource = RCC_PLLSOURCE_MSI;
  RCC_OscInitStruct.PLL.PLLM = 4;
  RCC_OscInitStruct.PLL.PLLN = 16;
  RCC_OscInitStruct.PLL.PLLP = RCC_PLLP_DIV24;
  RCC_OscInitStruct.PLL.PLLQ = RCC_PLLQ_DIV8;
  RCC_OscInitStruct.PLL.PLLR = RCC_PLLR_DIV2;
  if (HAL_RCC_OscConfig(&RCC_OscInitStruct) != HAL_OK)
  {
    Error_Handler();
  }
  /**Initializes the CPU, AHB and APB busses clocks
  */
  RCC_ClkInitStruct.ClockType = RCC_CLOCKTYPE_HCLK|RCC_CLOCKTYPE_SYSCLK
                              |RCC_CLOCKTYPE_PCLK1|RCC_CLOCKTYPE_PCLK2;
  RCC_ClkInitStruct.SYSCLKSource = RCC_SYSCLKSOURCE_MSI;
  RCC_ClkInitStruct.AHBCLKDivider = RCC_SYSCLK_DIV1;
  RCC_ClkInitStruct.APB1CLKDivider = RCC_HCLK_DIV1;
  RCC_ClkInitStruct.APB2CLKDivider = RCC_HCLK_DIV1;

  if (HAL_RCC_ClockConfig(&RCC_ClkInitStruct, FLASH_LATENCY_2) != HAL_OK)
  {
    Error_Handler();
  }
  PeriphClkInit.PeriphClockSelection = RCC_PERIPHCLK_RTC|RCC_PERIPHCLK_USART1
                              |RCC_PERIPHCLK_LPUART1|RCC_PERIPHCLK_SAI1
                              |RCC_PERIPHCLK_SAI2|RCC_PERIPHCLK_I2C1
                              |RCC_PERIPHCLK_I2C2|RCC_PERIPHCLK_DFSDM1
                              |RCC_PERIPHCLK_USB|RCC_PERIPHCLK_RNG
                              |RCC_PERIPHCLK_ADC;
  PeriphClkInit.Usart1ClockSelection = RCC_USART1CLKSOURCE_PCLK2;
  PeriphClkInit.Lpuart1ClockSelection = RCC_LPUART1CLKSOURCE_PCLK1;
  PeriphClkInit.I2c1ClockSelection = RCC_I2C1CLKSOURCE_SYSCLK;
  PeriphClkInit.I2c2ClockSelection = RCC_I2C2CLKSOURCE_SYSCLK;
  PeriphClkInit.Sai1ClockSelection = RCC_SAI1CLKSOURCE_PLL;
  PeriphClkInit.Sai2ClockSelection = RCC_SAI2CLKSOURCE_PLL;
  PeriphClkInit.AdcClockSelection = RCC_ADCCLKSOURCE_SYSCLK;
  PeriphClkInit.Dfsdm1ClockSelection = RCC_DFSDM1CLKSOURCE_PCLK;
  PeriphClkInit.RTCClockSelection = RCC_RTCCLKSOURCE_LSE;
  PeriphClkInit.UsbClockSelection = RCC_USBCLKSOURCE_HSI48;
  PeriphClkInit.RngClockSelection = RCC_RNGCLKSOURCE_HSI48;
  if (HAL_RCCEx_PeriphCLKConfig(&PeriphClkInit) != HAL_OK)
  {
    Error_Handler();
  }
  HAL_RCC_MCOConfig(RCC_MCO1, RCC_MCO1SOURCE_MSI, RCC_MCODIV_2);
  /**Configure the main internal regulator output voltage
  */
  if (HAL_PWREx_ControlVoltageScaling(PWR_REGULATOR_VOLTAGE_SCALE2) != HAL_OK)
  {
    Error_Handler();
  }
  /**Enable the SYSCFG APB clock
  */
  __HAL_RCC_CRS_CLK_ENABLE();
  /**Configures CRS
  */
  RCC_CRSInitStruct.Prescaler = RCC_CRS_SYNC_DIV1;
  RCC_CRSInitStruct.Source = RCC_CRS_SYNC_SOURCE_USB;
  RCC_CRSInitStruct.Polarity = RCC_CRS_SYNC_POLARITY_RISING;
  RCC_CRSInitStruct.ReloadValue = __HAL_RCC_CRS_RELOADVALUE_CALCULATE(48000000,1000);
  RCC_CRSInitStruct.ErrorLimitValue = 34;
  RCC_CRSInitStruct.HSI48CalibrationValue = 32;

  HAL_RCCEx_CRSConfig(&RCC_CRSInitStruct);
}

void HAL_TIM_PeriodElapsedCallback(TIM_HandleTypeDef *htim)
{
  if (htim->Instance == TIM2) {
    HAL_IncTick();
  }
}

void Error_Handler(void)
{
}

/************************ (C) COPYRIGHT STMicroelectronics *****END OF FILE****/

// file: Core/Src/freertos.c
/* USER CODE BEGIN Header */
/**
  ******************************************************************************
  * File Name          : freertos.c
  * Description        : Code for freertos applications
  ******************************************************************************
  * This notice applies to any and all portions of this file
  * that are not between comment pairs USER CODE BEGIN and
  * USER CODE END. Other portions of this file, whether
  * inserted by the user or by software development tools
  * are owned by their respective copyright owners.
  *
  * Copyright (c) 2019 STMicroelectronics International N.V.
  * All rights reserved.
  *
  * Redistribution and use in source and binary forms, with or without
  * modification, are permitted, provided that the following conditions are met:
  *
  * 1. Redistribution of source code must retain the above copyright notice,
  *    this list of conditions and the following disclaimer.
  * 2. Redistributions in binary form must reproduce the above copyright notice,
  *    this list of conditions and the following disclaimer in the documentation
  *    and/or other materials provided with the distribution.
  * 3. Neither the name of STMicroelectronics nor the names of other
  *    contributors to this software may be used to endorse or promote products
  *    derived from this software without specific written permission.
  * 4. This software, including modifications and/or derivative works of this
  *    software, must execute solely and exclusively on microcontroller or
  *    microprocessor devices manufactured by or for STMicroelectronics.
  * 5. Redistribution and use of this software other than as permitted under
  *    this license is void and will automatically terminate your rights under
  *    this license.
  *
  * THIS SOFTWARE IS PROVIDED BY STMICROELECTRONICS AND CONTRIBUTORS "AS IS"
  * AND ANY EXPRESS, IMPLIED OR STATUTORY WARRANTIES, INCLUDING, BUT NOT
  * LIMITED TO, THE IMPLIED WARRANTIES OF MERCHANTABILITY, FITNESS FOR A
  * PARTICULAR PURPOSE AND NON-INFRINGEMENT OF THIRD PARTY INTELLECTUAL PROPERTY
  * RIGHTS ARE DISCLAIMED TO THE FULLEST EXTENT PERMITTED BY LAW. IN NO EVENT
  * SHALL STMICROELECTRONICS OR CONTRIBUTORS BE LIABLE FOR ANY DIRECT, INDIRECT,
  * INCIDENTAL, SPECIAL, EXEMPLARY, OR CONSEQUENTIAL DAMAGES (INCLUDING, BUT NOT
  * LIMITED TO, PROCUREMENT OF SUBSTITUTE GOODS OR SERVICES; LOSS OF USE, DATA,
  * OR PROFITS; OR BUSINESS INTERRUPTION) HOWEVER CAUSED AND ON ANY THEORY OF
  * LIABILITY, WHETHER IN CONTRACT, STRICT LIABILITY, OR TORT (INCLUDING
  * NEGLIGENCE OR OTHERWISE) ARISING IN ANY WAY OUT OF THE USE OF THIS SOFTWARE,
  * EVEN IF ADVISED OF THE POSSIBILITY OF SUCH DAMAGE.
  *
  ******************************************************************************
  */
/* USER CODE END Header */

#include "FreeRTOS.h"
#include "task.h"
#include "main.h"
#include "cmsis_os.h"

osThreadId defaultTaskHandle;
osThreadId usbToHostTaskHandle;
osThreadId usbFromHostTaskHandle;
osThreadId hygroTaskHandle;
osThreadId baroTaskHandle;
osThreadId gyroTaskHandle;
osThreadId lcdTaskHandle;
osThreadId tcxo20MhzTaskHandle;
osThreadId ax5243TaskHandle;
osThreadId sx1276TaskHandle;
osThreadId controllerTaskHandle;
osThreadId si5338TaskHandle;
osThreadId audioAdcTaskHandle;
osThreadId audioDacTaskHandle;
osMessageQId usbToHostQueueHandle;
osMessageQId usbFromHostQueueHandle;
osMessageQId controllerInQueueHandle;
osMessageQId controllerOutQueueHandle;
osMessageQId loraMacQueueHandle;
osTimerId baroTimerHandle;
osTimerId hygroTimerHandle;
osTimerId defaultTimerHandle;
osTimerId gyroTimerHandle;
osTimerId controllerTimerHandle;
osTimerId tcxoTimerHandle;
osTimerId audioAdcTimerHandle;
osTimerId audioDacTimerHandle;
osSemaphoreId c2Ax5243_BSemHandle;
osSemaphoreId c2Sx1276_BSemHandle;
osSemaphoreId c2Si5338_BSemHandle;
osSemaphoreId c2Tcxo_BSemHandle;
osSemaphoreId c2Baro_BSemHandle;
osSemaphoreId c2Gyro_BSemHandle;
osSemaphoreId c2Hygro_BSemHandle;
osSemaphoreId c2Lcd_BSemHandle;
osSemaphoreId c2Default_BSemHandle;
osSemaphoreId i2c1_BSemHandle;
osSemaphoreId i2c2_BSemHandle;
osSemaphoreId i2c3_BSemHandle;
osSemaphoreId i2c4_BSemHandle;
osSemaphoreId spi1_BSemHandle;
osSemaphoreId spi3_BSemHandle;
osSemaphoreId cQin_BSemHandle;
osSemaphoreId cQout_BSemHandle;
osSemaphoreId c2AudioAdc_BSemHandle;
osSemaphoreId c2AudioDac_BSemHandle;
osSemaphoreId c2usbToHost_BSemHandle;
osSemaphoreId c2usbFromHost_BSemHandle;
osSemaphoreId usb_BSemHandle;

void StartDefaultTask(void const * argument);
void StartUsbToHostTask(void const * argument);
void StartUsbFromHostTask(void const * argument);
void StartHygroTask(void const * argument);
void StartBaroTask(void const * argument);
void StartGyroTask(void const * argument);
void StartLcdTask(void const * argument);
void StartTcxo20MhzTask(void const * argument);
void StartAx5243Task(void const * argument);
void StartSx1276Task(void const * argument);
void StartControllerTask(void const * argument);
void StartSi5338Task(void const * argument);
void StartAudioAdcTask(void const * argument);
void StartAudioDacTask(void const * argument);
void rtosBaroTimerCallback(void const * argument);
void rtosHygroTimerCallback(void const * argument);
void rtosDefaultTimerCallback(void const * argument);
void rtosGyroTimerCallback(void const * argument);
void rtosControllerTimerCallback(void const * argument);
void rtosTcxoTimerCallback(void const * argument);
void rtosAudioAdcTimerCallback(void const * argument);
void rtosAudioDacTimerCallback(void const * argument);

void MX_FREERTOS_Init(void); /* (MISRA C 2004 rule 8.1) */

/* Hook prototypes */
void configureTimerForRunTimeStats(void);
unsigned long getRunTimeCounterValue(void);
void vApplicationIdleHook(void);
void vApplicationStackOverflowHook(TaskHandle_t xTask, signed char *pcTaskName);
void vApplicationMallocFailedHook(void);

/* USER CODE BEGIN 1 */
/* Functions needed when configGENERATE_RUN_TIME_STATS is on */
__weak void configureTimerForRunTimeStats(void)
{

}

__weak unsigned long getRunTimeCounterValue(void)
{
return 0;
}
/* USER CODE END 1 */

/* USER CODE BEGIN 2 */
__weak void vApplicationIdleHook( void )
{
   /* vApplicationIdleHook() will only be called if configUSE_IDLE_HOOK is set
   to 1 in FreeRTOSConfig.h. It will be called on each iteration of the idle
   task. It is essential that code added to this hook function never attempts
   to block in any way (for example, call xQueueReceive() with a block time
   specified, or call vTaskDelay()). If the application makes use of the
   vTaskDelete() API function (as this demo application does) then it is also
   important that vApplicationIdleHook() is permitted to return to its calling
   function, because it is the responsibility of the idle task to clean up
   memory allocated by the kernel to any task that has since been deleted. */
}
/* USER CODE END 2 */

/* USER CODE BEGIN 4 */
__weak void vApplicationStackOverflowHook(TaskHandle_t xTask, signed char *pcTaskName)
{
   /* Run time stack overflow checking is performed if
   configCHECK_FOR_STACK_OVERFLOW is defined to 1 or 2. This hook function is
   called if a stack overflow is detected. */
}
/* USER CODE END 4 */

/* USER CODE BEGIN 5 */
__weak void vApplicationMallocFailedHook(void)
{
   /* vApplicationMallocFailedHook() will only be called if
   configUSE_MALLOC_FAILED_HOOK is set to 1 in FreeRTOSConfig.h. It is a hook
   function that will get called if a call to pvPortMalloc() fails.
   pvPortMalloc() is called internally by the kernel whenever a task, queue,
   timer or semaphore is created. It is also called by various parts of the
   demo application. If heap_1.c or heap_2.c are used, then the size of the
   heap available to pvPortMalloc() is defined by configTOTAL_HEAP_SIZE in
   FreeRTOSConfig.h, and the xPortGetFreeHeapSize() API function can be used
   to query the size of free heap space that remains (although it does not
   provide information on how the remaining heap might be fragmented). */
}
/* USER CODE END 5 */

void MX_FREERTOS_Init(void) {

  /* Create the semaphores(s) */
  /* definition and creation of c2Ax5243_BSem */
  osSemaphoreDef(c2Ax5243_BSem);
  c2Ax5243_BSemHandle = osSemaphoreCreate(osSemaphore(c2Ax5243_BSem), 1);

  /* definition and creation of c2Sx1276_BSem */
  osSemaphoreDef(c2Sx1276_BSem);
  c2Sx1276_BSemHandle = osSemaphoreCreate(osSemaphore(c2Sx1276_BSem), 1);

  /* definition and creation of c2Si5338_BSem */
  osSemaphoreDef(c2Si5338_BSem);
  c2Si5338_BSemHandle = osSemaphoreCreate(osSemaphore(c2Si5338_BSem), 1);

  /* definition and creation of c2Tcxo_BSem */
  osSemaphoreDef(c2Tcxo_BSem);
  c2Tcxo_BSemHandle = osSemaphoreCreate(osSemaphore(c2Tcxo_BSem), 1);

  /* definition and creation of c2Baro_BSem */
  osSemaphoreDef(c2Baro_BSem);
  c2Baro_BSemHandle = osSemaphoreCreate(osSemaphore(c2Baro_BSem), 1);

  /* definition and creation of c2Gyro_BSem */
  osSemaphoreDef(c2Gyro_BSem);
  c2Gyro_BSemHandle = osSemaphoreCreate(osSemaphore(c2Gyro_BSem), 1);

  /* definition and creation of c2Hygro_BSem */
  osSemaphoreDef(c2Hygro_BSem);
  c2Hygro_BSemHandle = osSemaphoreCreate(osSemaphore(c2Hygro_BSem), 1);

  /* definition and creation of c2Lcd_BSem */
  osSemaphoreDef(c2Lcd_BSem);
  c2Lcd_BSemHandle = osSemaphoreCreate(osSemaphore(c2Lcd_BSem), 1);

  /* definition and creation of c2Default_BSem */
  osSemaphoreDef(c2Default_BSem);
  c2Default_BSemHandle = osSemaphoreCreate(osSemaphore(c2Default_BSem), 1);

  /* definition and creation of i2c1_BSem */
  osSemaphoreDef(i2c1_BSem);
  i2c1_BSemHandle = osSemaphoreCreate(osSemaphore(i2c1_BSem), 1);

  /* definition and creation of i2c2_BSem */
  osSemaphoreDef(i2c2_BSem);
  i2c2_BSemHandle = osSemaphoreCreate(osSemaphore(i2c2_BSem), 1);

  /* definition and creation of i2c3_BSem */
  osSemaphoreDef(i2c3_BSem);
  i2c3_BSemHandle = osSemaphoreCreate(osSemaphore(i2c3_BSem), 1);

  /* definition and creation of i2c4_BSem */
  osSemaphoreDef(i2c4_BSem);
  i2c4_BSemHandle = osSemaphoreCreate(osSemaphore(i2c4_BSem), 1);

  /* definition and creation of spi1_BSem */
  osSemaphoreDef(spi1_BSem);
  spi1_BSemHandle = osSemaphoreCreate(osSemaphore(spi1_BSem), 1);

  /* definition and creation of spi3_BSem */
  osSemaphoreDef(spi3_BSem);
  spi3_BSemHandle = osSemaphoreCreate(osSemaphore(spi3_BSem), 1);

  /* definition and creation of cQin_BSem */
  osSemaphoreDef(cQin_BSem);
  cQin_BSemHandle = osSemaphoreCreate(osSemaphore(cQin_BSem), 1);

  /* definition and creation of cQout_BSem */
  osSemaphoreDef(cQout_BSem);
  cQout_BSemHandle = osSemaphoreCreate(osSemaphore(cQout_BSem), 1);

  /* definition and creation of c2AudioAdc_BSem */
  osSemaphoreDef(c2AudioAdc_BSem);
  c2AudioAdc_BSemHandle = osSemaphoreCreate(osSemaphore(c2AudioAdc_BSem), 1);

  /* definition and creation of c2AudioDac_BSem */
  osSemaphoreDef(c2AudioDac_BSem);
  c2AudioDac_BSemHandle = osSemaphoreCreate(osSemaphore(c2AudioDac_BSem), 1);

  /* definition and creation of c2usbToHost_BSem */
  osSemaphoreDef(c2usbToHost_BSem);
  c2usbToHost_BSemHandle = osSemaphoreCreate(osSemaphore(c2usbToHost_BSem), 1);

  /* definition and creation of c2usbFromHost_BSem */
  osSemaphoreDef(c2usbFromHost_BSem);
  c2usbFromHost_BSemHandle = osSemaphoreCreate(osSemaphore(c2usbFromHost_BSem), 1);

  /* definition and creation of usb_BSem */
  osSemaphoreDef(usb_BSem);
  usb_BSemHandle = osSemaphoreCreate(osSemaphore(usb_BSem), 1);

  /* Create the timer(s) */
  /* definition and creation of baroTimer */
  osTimerDef(baroTimer, rtosBaroTimerCallback);
  baroTimerHandle = osTimerCreate(osTimer(baroTimer), osTimerPeriodic, NULL);

  /* definition and creation of hygroTimer */
  osTimerDef(hygroTimer, rtosHygroTimerCallback);
  hygroTimerHandle = osTimerCreate(osTimer(hygroTimer), osTimerPeriodic, NULL);

  /* definition and creation of defaultTimer */
  osTimerDef(defaultTimer, rtosDefaultTimerCallback);
  defaultTimerHandle = osTimerCreate(osTimer(defaultTimer), osTimerPeriodic, NULL);

  /* definition and creation of gyroTimer */
  osTimerDef(gyroTimer, rtosGyroTimerCallback);
  gyroTimerHandle = osTimerCreate(osTimer(gyroTimer), osTimerPeriodic, NULL);

  /* definition and creation of controllerTimer */
  osTimerDef(controllerTimer, rtosControllerTimerCallback);
  controllerTimerHandle = osTimerCreate(osTimer(controllerTimer), osTimerPeriodic, NULL);

  /* definition and creation of tcxoTimer */
  osTimerDef(tcxoTimer, rtosTcxoTimerCallback);
  tcxoTimerHandle = osTimerCreate(osTimer(tcxoTimer), osTimerPeriodic, NULL);

  /* definition and creation of audioAdcTimer */
  osTimerDef(audioAdcTimer, rtosAudioAdcTimerCallback);
  audioAdcTimerHandle = osTimerCreate(osTimer(audioAdcTimer), osTimerPeriodic, NULL);

  /* definition and creation of audioDacTimer */
  osTimerDef(audioDacTimer, rtosAudioDacTimerCallback);
  audioDacTimerHandle = osTimerCreate(osTimer(audioDacTimer), osTimerPeriodic, NULL);

  /* Create the thread(s) */
  /* definition and creation of defaultTask */
  osThreadDef(defaultTask, StartDefaultTask, osPriorityBelowNormal, 0, 256);
  defaultTaskHandle = osThreadCreate(osThread(defaultTask), NULL);

  /* definition and creation of usbToHostTask */
  osThreadDef(usbToHostTask, StartUsbToHostTask, osPriorityNormal, 0, 128);
  usbToHostTaskHandle = osThreadCreate(osThread(usbToHostTask), NULL);

  /* definition and creation of usbFromHostTask */
  osThreadDef(usbFromHostTask, StartUsbFromHostTask, osPriorityNormal, 0, 128);
  usbFromHostTaskHandle = osThreadCreate(osThread(usbFromHostTask), NULL);

  /* definition and creation of hygroTask */
  osThreadDef(hygroTask, StartHygroTask, osPriorityNormal, 0, 256);
  hygroTaskHandle = osThreadCreate(osThread(hygroTask), NULL);

  /* definition and creation of baroTask */
  osThreadDef(baroTask, StartBaroTask, osPriorityNormal, 0, 256);
  baroTaskHandle = osThreadCreate(osThread(baroTask), NULL);

  /* definition and creation of gyroTask */
  osThreadDef(gyroTask, StartGyroTask, osPriorityNormal, 0, 256);
  gyroTaskHandle = osThreadCreate(osThread(gyroTask), NULL);

  /* definition and creation of lcdTask */
  osThreadDef(lcdTask, StartLcdTask, osPriorityNormal, 0, 256);
  lcdTaskHandle = osThreadCreate(osThread(lcdTask), NULL);

  /* definition and creation of tcxo20MhzTask */
  osThreadDef(tcxo20MhzTask, StartTcxo20MhzTask, osPriorityNormal, 0, 256);
  tcxo20MhzTaskHandle = osThreadCreate(osThread(tcxo20MhzTask), NULL);

  /* definition and creation of ax5243Task */
  osThreadDef(ax5243Task, StartAx5243Task, osPriorityAboveNormal, 0, 512);
  ax5243TaskHandle = osThreadCreate(osThread(ax5243Task), NULL);

  /* definition and creation of sx1276Task */
  osThreadDef(sx1276Task, StartSx1276Task, osPriorityAboveNormal, 0, 512);
  sx1276TaskHandle = osThreadCreate(osThread(sx1276Task), NULL);

  /* definition and creation of controllerTask */
  osThreadDef(controllerTask, StartControllerTask, osPriorityLow, 0, 256);
  controllerTaskHandle = osThreadCreate(osThread(controllerTask), NULL);

  /* definition and creation of si5338Task */
  osThreadDef(si5338Task, StartSi5338Task, osPriorityNormal, 0, 256);
  si5338TaskHandle = osThreadCreate(osThread(si5338Task), NULL);

  /* definition and creation of audioAdcTask */
  osThreadDef(audioAdcTask, StartAudioAdcTask, osPriorityNormal, 0, 256);
  audioAdcTaskHandle = osThreadCreate(osThread(audioAdcTask), NULL);

  /* definition and creation of audioDacTask */
  osThreadDef(audioDacTask, StartAudioDacTask, osPriorityNormal, 0, 256);
  audioDacTaskHandle = osThreadCreate(osThread(audioDacTask), NULL);

  /* Create the queue(s) */
  /* definition and creation of usbToHostQueue */
  osMessageQDef(usbToHostQueue, 4096, uint8_t);
  usbToHostQueueHandle = osMessageCreate(osMessageQ(usbToHostQueue), NULL);

  /* definition and creation of usbFromHostQueue */
  osMessageQDef(usbFromHostQueue, 32, uint8_t);
  usbFromHostQueueHandle = osMessageCreate(osMessageQ(usbFromHostQueue), NULL);

  /* definition and creation of controllerInQueue */
  osMessageQDef(controllerInQueue, 8, uint32_t);
  controllerInQueueHandle = osMessageCreate(osMessageQ(controllerInQueue), NULL);

  /* definition and creation of controllerOutQueue */
  osMessageQDef(controllerOutQueue, 32, uint32_t);
  controllerOutQueueHandle = osMessageCreate(osMessageQ(controllerOutQueue), NULL);

  /* definition and creation of loraMacQueue */
  osMessageQDef(loraMacQueue, 32, uint8_t);
  loraMacQueueHandle = osMessageCreate(osMessageQ(loraMacQueue), NULL);

}

void StartDefaultTask(void const * argument)
{

  for(;;)
  {
    osDelay(1);
  }
}

void StartUsbToHostTask(void const * argument)
{
  for(;;)
  {
    osDelay(1);
  }
}

void StartUsbFromHostTask(void const * argument)
{
  for(;;)
  {
    osDelay(1);
  }
}

void StartHygroTask(void const * argument)
{
  for(;;)
  {
    osDelay(1);
  }
}

void StartBaroTask(void const * argument)
{
  for(;;)
  {
    osDelay(1);
  }
}

void StartGyroTask(void const * argument)
{
  for(;;)
  {
    osDelay(1);
  }
}

void StartLcdTask(void const * argument)
{
  for(;;)
  {
    osDelay(1);
  }
}

void StartTcxo20MhzTask(void const * argument)
{
  for(;;)
  {
    osDelay(1);
  }
}

void StartAx5243Task(void const * argument)
{
  for(;;)
  {
    osDelay(1);
  }
}

void StartSx1276Task(void const * argument)
{
  for(;;)
  {
    osDelay(1);
  }
}

void StartControllerTask(void const * argument)
{
  for(;;)
  {
    osDelay(1);
  }
}

void StartSi5338Task(void const * argument)
{
  for(;;)
  {
    osDelay(1);
  }
}

void StartAudioAdcTask(void const * argument)
{
  for(;;)
  {
    osDelay(1);
  }
}

void StartAudioDacTask(void const * argument)
{
  for(;;)
  {
    osDelay(1);
  }
}

/* rtosBaroTimerCallback function */
void rtosBaroTimerCallback(void const * argument)
{
}

/* rtosHygroTimerCallback function */
void rtosHygroTimerCallback(void const * argument)
{
}

/* rtosDefaultTimerCallback function */
void rtosDefaultTimerCallback(void const * argument)
{
}

/* rtosGyroTimerCallback function */
void rtosGyroTimerCallback(void const * argument)
{
}

/* rtosControllerTimerCallback function */
void rtosControllerTimerCallback(void const * argument)
{
}

/* rtosTcxoTimerCallback function */
void rtosTcxoTimerCallback(void const * argument)
{
}

/* rtosAudioAdcTimerCallback function */
void rtosAudioAdcTimerCallback(void const * argument)
{
}

/* rtosAudioDacTimerCallback function */
void rtosAudioDacTimerCallback(void const * argument)
{
}

/************************ (C) COPYRIGHT STMicroelectronics *****END OF FILE****/
